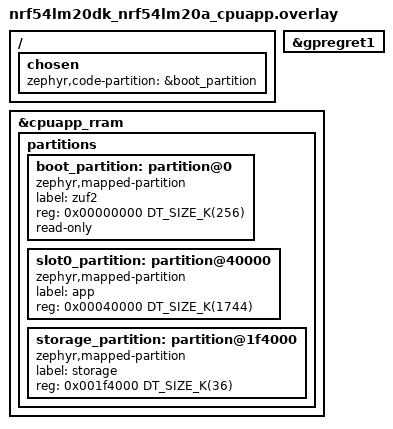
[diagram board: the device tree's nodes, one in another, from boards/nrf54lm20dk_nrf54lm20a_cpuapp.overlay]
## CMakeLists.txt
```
cmake_minimum_required(VERSION 3.20.0)

find_package(Zephyr REQUIRED HINTS $ENV{ZEPHYR_BASE})
project(zuf2)

target_include_directories(app PRIVATE src)

target_sources(app PRIVATE
	src/boot.c
	src/main.c
	src/uf2_disk.c
	src/uf2_writer.c
	src/usb_descriptors.c
)
```

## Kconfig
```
menuconfig ZUF2
	bool "zuf2 UF2 bootloader"
	default y
	help
	  Build a small UF2-over-USB-MSC bootloader that writes a
	  devicetree-defined application partition and chain-loads it directly.

if ZUF2

config ZUF2_ALWAYS_ENTER
	bool "Always stay in UF2 mode"
	default n
	help
	  Stay in the bootloader even when a valid application is present.
	  This is useful during bring-up.

config ZUF2_BOOT_BUTTON
	bool "Bootloader entry button"
	default y
	depends on GPIO
	help
	  If the board has a devicetree sw0 alias, holding it at reset keeps
	  the bootloader in UF2 mode.

config ZUF2_DOUBLE_TAP_RESET
	bool "Double-tap reset bootloader entry"
	default y
	select RETAINED_MEM if DT_HAS_NORDIC_NRF_GPREGRET_ENABLED
	help
	  Enter UF2 mode when the board is reset twice within
	  ZUF2_DOUBLE_TAP_DELAY_MS while a valid application is present.
	  This matches the common Adafruit-style double-reset bootloader
	  gesture.

config ZUF2_DOUBLE_TAP_DELAY_MS
	int "Double-tap reset window in milliseconds"
	default 500
	range 1 10000
	help
	  Time after the first reset that zuf2 waits for a second reset before
	  booting the application. This is used when ZUF2_DOUBLE_TAP_RESET is
	  enabled.

config ZUF2_DOUBLE_TAP_MAGIC
	hex "Double-tap reset marker byte"
	default 0x5a
	range 0x01 0xff
	help
	  Marker value stored in retained state during the double-tap reset
	  window. Change this if another firmware component uses the same
	  retained marker value.

config ZUF2_REQUIRE_FAMILY_ID
	bool "Require UF2 family ID"
	default y
	help
	  Only accept UF2 blocks that set the family-ID flag and match
	  ZUF2_FAMILY_ID.

config ZUF2_FAMILY_ID
	hex "UF2 family ID"
	default 0x016f65e4
	help
	  UF2 family ID accepted by this bootloader. The default was randomly
	  generated for the nRF54LM20 bring-up target because the upstream UF2
	  family list does not currently define an nRF54 family.

config ZUF2_MAX_EXTRA_UF2_BLOCKS
	int "Extra UF2 tracking blocks in blocks"
	default 2048
	help
	  Number of non-application UF2 blocks that can be tracked for
	  completion. Source-embedded UF2 files may contain blocks beyond the
	  application partition payload.

config ZUF2_RESET_DELAY_MS
	int "Reset delay after UF2 write in milliseconds"
	default 500
	help
	  Delay after all UF2 blocks have been received before rebooting into
	  the newly written application.

config ZUF2_DISK_SECTOR_COUNT
	int "Virtual UF2 disk size in sectors"
	default 8192
	help
	  Number of 512-byte sectors reported by the virtual FAT16 disk.
	  Increase this if the generated CURRENT.UF2 file does not fit.

config ZUF2_USB_VID
	hex "USB vendor ID"
	default 0x1209
	help
	  USB vendor ID used by the bootloader MSC device. Replace this for any
	  production device.

config ZUF2_USB_PID
	hex "USB product ID"
	default 0x5a02
	help
	  USB product ID used by the bootloader MSC device. Replace this for any
	  production device.

config ZUF2_USB_MANUFACTURER
	string "USB manufacturer string"
	default "zuf2"
	help
	  USB manufacturer string descriptor.

config ZUF2_USB_PRODUCT
	string "USB product string"
	default "zuf2 UF2 Bootloader"
	help
	  USB product string descriptor.

config ZUF2_VOLUME_LABEL
	string "UF2 volume label"
	default "ZUF2BOOT"
	help
	  FAT volume label. The value is padded or truncated to the FAT 11-byte
	  volume label field.

config ZUF2_MODEL
	string "UF2 model string"
	default "nRF54LM20 DK"
	help
	  Human-readable model line exposed in INFO_UF2.TXT.

config ZUF2_BOARD_ID
	string "UF2 board ID string"
	default "nRF54LM20-DK-zuf2-v0"
	help
	  Machine-readable Board-ID exposed in INFO_UF2.TXT.

config ZUF2_INDEX_URL
	string "UF2 index URL"
	default "https://github.com/microsoft/uf2"
	help
	  URL used by INDEX.HTM on the virtual UF2 disk.

module = ZUF2
module-str = zuf2 bootloader
source "$(ZEPHYR_BASE)/subsys/logging/Kconfig.template.log_config"

endif

source "Kconfig.zephyr"
```

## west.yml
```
# Copyright (c) 2021 Nordic Semiconductor ASA
# SPDX-License-Identifier: Apache-2.0

manifest:
  remotes:
    - name: ncs
      url-base: https://github.com/nrfconnect

  projects:
    - name: nrf
      remote: ncs
      repo-path: sdk-nrf
      revision: main
      import: true
```

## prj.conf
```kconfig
CONFIG_ZUF2=y
CONFIG_USE_DT_CODE_PARTITION=y

CONFIG_MAIN_STACK_SIZE=4096
CONFIG_SYSTEM_WORKQUEUE_STACK_SIZE=2048
CONFIG_BOOT_BANNER=n
CONFIG_INIT_ARCH_HW_AT_BOOT=y
CONFIG_HW_STACK_PROTECTION=y

CONFIG_LOG=y
CONFIG_ZUF2_LOG_LEVEL_INF=y
CONFIG_USBD_LOG_LEVEL_WRN=y
CONFIG_UDC_DRIVER_LOG_LEVEL_WRN=y

CONFIG_FLASH=y
CONFIG_FLASH_MAP=y
CONFIG_FLASH_PAGE_LAYOUT=y

CONFIG_DISK_ACCESS=y
CONFIG_USB_DEVICE_STACK_NEXT=y
CONFIG_USBD_MSC_CLASS=y
CONFIG_USBD_MSC_LUNS_PER_INSTANCE=1
CONFIG_USBD_MSC_SCSI_BUFFER_SIZE=512

CONFIG_REBOOT=y
CONFIG_GPIO=y
CONFIG_SERIAL=y
CONFIG_UART_LINE_CTRL=y
CONFIG_STDOUT_CONSOLE=y
CONFIG_CDC_ACM_SERIAL_INITIALIZE_AT_BOOT=n
```

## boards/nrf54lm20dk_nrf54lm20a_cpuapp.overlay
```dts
/delete-node/ &boot_partition;
/delete-node/ &slot0_partition;
/delete-node/ &slot1_partition;
/delete-node/ &storage_partition;

/ {
	chosen {
		zephyr,code-partition = &boot_partition;
	};
};

&gpregret1 {
	status = "okay";
};

&cpuapp_rram {
	partitions {
		ranges;
		#address-cells = <1>;
		#size-cells = <1>;

		boot_partition: partition@0 {
			compatible = "zephyr,mapped-partition";
			label = "zuf2";
			reg = <0x00000000 DT_SIZE_K(256)>;
			read-only;
		};

		slot0_partition: partition@40000 {
			compatible = "zephyr,mapped-partition";
			label = "app";
			reg = <0x00040000 DT_SIZE_K(1744)>;
		};

		storage_partition: partition@1f4000 {
			compatible = "zephyr,mapped-partition";
			label = "storage";
			reg = <0x001f4000 DT_SIZE_K(36)>;
		};
	};
};
```

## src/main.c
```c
#include "app_partition.h"
#include "boot.h"
#include "usb_descriptors.h"

#include <zephyr/device.h>
#include <zephyr/devicetree.h>
#include <zephyr/drivers/gpio.h>
#include <zephyr/drivers/retained_mem.h>
#include <zephyr/kernel.h>
#include <zephyr/linker/section_tags.h>
#include <zephyr/logging/log.h>

LOG_MODULE_REGISTER(zuf2, CONFIG_ZUF2_LOG_LEVEL);

#if DT_NODE_HAS_STATUS(DT_ALIAS(sw0), okay)
#define HAS_BOOT_BUTTON 1
static const struct gpio_dt_spec boot_button = GPIO_DT_SPEC_GET(DT_ALIAS(sw0), gpios);
#else
#define HAS_BOOT_BUTTON 0
#endif

#if DT_HAS_COMPAT_STATUS_OKAY(nordic_nrf_gpregret)
#define HAS_DOUBLE_TAP_RETENTION 1
static const struct device *const double_tap_retention =
	DEVICE_DT_GET(DT_INST(0, nordic_nrf_gpregret));
#else
#define HAS_DOUBLE_TAP_RETENTION 0
struct double_tap_state {
	uint32_t magic;
	uint32_t magic_inv;
	uint32_t app_base;
};
static struct double_tap_state double_tap_state __noinit;
#endif

#define DOUBLE_TAP_MAGIC ((uint8_t)CONFIG_ZUF2_DOUBLE_TAP_MAGIC)
#define DOUBLE_TAP_MAGIC_INV (~DOUBLE_TAP_MAGIC)

static bool boot_button_pressed(void)
{
	int ret;

	if (!IS_ENABLED(CONFIG_ZUF2_BOOT_BUTTON) || !HAS_BOOT_BUTTON) {
		return false;
	}

#if HAS_BOOT_BUTTON
	if (!device_is_ready(boot_button.port)) {
		LOG_WRN("boot button device is not ready");
		return false;
	}

	ret = gpio_pin_configure_dt(&boot_button, GPIO_INPUT);
	if (ret != 0) {
		LOG_WRN("failed to configure boot button: %d", ret);
		return false;
	}

	ret = gpio_pin_get_dt(&boot_button);
	if (ret < 0) {
		LOG_WRN("failed to read boot button: %d", ret);
		return false;
	}

	return ret > 0;
#else
	return false;
#endif
}

static void double_tap_clear(void)
{
#if HAS_DOUBLE_TAP_RETENTION
	int ret;

	if (!device_is_ready(double_tap_retention)) {
		return;
	}

	ret = retained_mem_clear(double_tap_retention);
	if (ret != 0) {
		LOG_WRN("failed to clear double-tap marker: %d", ret);
	}
#else
	double_tap_state.magic = 0U;
	double_tap_state.magic_inv = 0U;
	double_tap_state.app_base = 0U;
#endif
}

static bool double_tap_is_armed(void)
{
	if (!IS_ENABLED(CONFIG_ZUF2_DOUBLE_TAP_RESET)) {
		return false;
	}

#if HAS_DOUBLE_TAP_RETENTION
	uint8_t marker;
	int ret;

	if (!device_is_ready(double_tap_retention)) {
		LOG_WRN("double-tap retention device is not ready");
		return false;
	}

	ret = retained_mem_read(double_tap_retention, 0, &marker, sizeof(marker));
	if (ret != 0) {
		LOG_WRN("failed to read double-tap marker: %d", ret);
		return false;
	}

	return marker == DOUBLE_TAP_MAGIC;
#else
	return IS_ENABLED(CONFIG_ZUF2_DOUBLE_TAP_RESET) &&
	       double_tap_state.magic == (uint32_t)DOUBLE_TAP_MAGIC &&
	       double_tap_state.magic_inv == (uint32_t)DOUBLE_TAP_MAGIC_INV &&
	       double_tap_state.app_base == ZUF2_APP_PARTITION_ADDRESS;
#endif
}

static void double_tap_arm(void)
{
#if HAS_DOUBLE_TAP_RETENTION
	uint8_t marker = DOUBLE_TAP_MAGIC;
	int ret;

	if (!device_is_ready(double_tap_retention)) {
		LOG_WRN("double-tap retention device is not ready");
		return;
	}

	ret = retained_mem_write(double_tap_retention, 0, &marker, sizeof(marker));
	if (ret != 0) {
		LOG_WRN("failed to arm double-tap marker: %d", ret);
	}
#else
	double_tap_state.magic = DOUBLE_TAP_MAGIC;
	double_tap_state.magic_inv = DOUBLE_TAP_MAGIC_INV;
	double_tap_state.app_base = ZUF2_APP_PARTITION_ADDRESS;
#endif
}

static void double_tap_wait_window(void)
{
	if (!IS_ENABLED(CONFIG_ZUF2_DOUBLE_TAP_RESET)) {
		return;
	}

	k_busy_wait(CONFIG_ZUF2_DOUBLE_TAP_DELAY_MS * 1000U);
	double_tap_clear();
}

int main(void)
{
	bool double_tap_detected = false;
	bool force_uf2;
	bool app_valid;

	if (double_tap_is_armed()) {
		double_tap_clear();
		double_tap_detected = true;
	} else {
		double_tap_arm();
	}

	app_valid = zuf2_app_is_valid();
	force_uf2 = IS_ENABLED(CONFIG_ZUF2_ALWAYS_ENTER) || boot_button_pressed() ||
		    double_tap_detected;

	if (!force_uf2 && app_valid) {
		double_tap_wait_window();
		zuf2_boot_app();
	}

	double_tap_clear();

	if (double_tap_detected) {
		LOG_INF("double-tap reset detected; staying in UF2 mode");
	} else if (force_uf2) {
		LOG_INF("staying in UF2 mode");
	} else {
		LOG_INF("no valid app found; staying in UF2 mode");
	}

	return zuf2_usb_start();
}
```

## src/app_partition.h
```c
#ifndef ZUF2_APP_PARTITION_H_
#define ZUF2_APP_PARTITION_H_

#include <zephyr/storage/flash_map.h>

#if PARTITION_EXISTS(slot0_partition)
#define ZUF2_APP_PARTITION_LABEL slot0_partition
#elif PARTITION_EXISTS(code_partition)
#define ZUF2_APP_PARTITION_LABEL code_partition
#else
#error "zuf2 requires a devicetree slot0_partition or code_partition for the application"
#endif

#define ZUF2_APP_PARTITION_ID PARTITION_ID(ZUF2_APP_PARTITION_LABEL)
#define ZUF2_APP_PARTITION_OFFSET PARTITION_OFFSET(ZUF2_APP_PARTITION_LABEL)
#define ZUF2_APP_PARTITION_ADDRESS PARTITION_ADDRESS(ZUF2_APP_PARTITION_LABEL)
#define ZUF2_APP_PARTITION_SIZE PARTITION_SIZE(ZUF2_APP_PARTITION_LABEL)

#endif
```

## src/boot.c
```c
#include "app_partition.h"
#include "boot.h"

#include <cmsis_core.h>
#include <zephyr/cache.h>
#include <zephyr/devicetree.h>
#include <zephyr/kernel.h>
#include <zephyr/logging/log.h>
#include <zephyr/sys/util.h>

LOG_MODULE_DECLARE(zuf2, CONFIG_ZUF2_LOG_LEVEL);

#define SRAM_NODE DT_CHOSEN(zephyr_sram)
#define SRAM_BASE DT_REG_ADDR(SRAM_NODE)
#define SRAM_SIZE DT_REG_SIZE(SRAM_NODE)
#define SRAM_END (SRAM_BASE + SRAM_SIZE)

#define APP_BASE ZUF2_APP_PARTITION_ADDRESS
#define APP_SIZE ZUF2_APP_PARTITION_SIZE
#define APP_END (APP_BASE + APP_SIZE)

static int read_app_vectors(uint32_t *sp, uint32_t *reset)
{
	const volatile uint32_t *vectors = (const volatile uint32_t *)APP_BASE;

	/* The application is executed in place, so read vectors from that mapping. */
	*sp = vectors[0];
	*reset = vectors[1];

	return 0;
}

bool zuf2_app_is_valid(void)
{
	uint32_t sp;
	uint32_t reset;
	uint32_t reset_addr;

	if (read_app_vectors(&sp, &reset) != 0) {
		return false;
	}

	if (sp == 0xffffffffU || reset == 0xffffffffU || sp == 0U || reset == 0U) {
		return false;
	}

	if ((sp < SRAM_BASE) || (sp > SRAM_END) || ((sp & 0x7U) != 0U)) {
		LOG_WRN("invalid app stack pointer 0x%08x", sp);
		return false;
	}

	if ((reset & 0x1U) == 0U) {
		LOG_WRN("invalid app reset vector 0x%08x", reset);
		return false;
	}

	reset_addr = reset & ~0x1U;
	if ((reset_addr < APP_BASE) || (reset_addr >= APP_END)) {
		LOG_WRN("app reset vector 0x%08x outside app partition", reset);
		return false;
	}

	return true;
}

void zuf2_boot_app(void)
{
	uint32_t sp;
	uint32_t reset;

	if (read_app_vectors(&sp, &reset) != 0) {
		return;
	}

	LOG_INF("booting app at 0x%08x", APP_BASE);
	k_busy_wait(2000);

	__disable_irq();

	for (size_t i = 0; i < ARRAY_SIZE(NVIC->ICER); i++) {
		NVIC->ICER[i] = 0xffffffffU;
	}

	for (size_t i = 0; i < ARRAY_SIZE(NVIC->ICPR); i++) {
		NVIC->ICPR[i] = 0xffffffffU;
	}

	SysTick->CTRL = 0;
	SysTick->LOAD = 0;
	SysTick->VAL = 0;
	SCB->ICSR |= SCB_ICSR_PENDSTCLR_Msk;

#ifndef CONFIG_CPU_CORTEX_M0
	SCB->SHCSR &= ~(SCB_SHCSR_USGFAULTENA_Msk | SCB_SHCSR_BUSFAULTENA_Msk |
			SCB_SHCSR_MEMFAULTENA_Msk);
#endif

	if ((CONTROL_SPSEL_Msk & __get_CONTROL()) != 0U) {
		__set_CONTROL(__get_CONTROL() & ~CONTROL_SPSEL_Msk);
	}

	__DSB();
	__ISB();

#if defined(CONFIG_CPU_CORTEX_M_HAS_VTOR)
	SCB->VTOR = APP_BASE;
#endif
	(void)sys_cache_instr_invd_all();

#if defined(CONFIG_CPU_CORTEX_M_HAS_SPLIM)
	__set_PSPLIM(0);
	__set_MSPLIM(0);
#endif

	__set_PSP(0);
	__asm__ volatile(
		"msr msp, %[app_sp]\n"
		"dsb 0xf\n"
		"isb 0xf\n"
		"bx %[app_reset]\n"
		:
		: [app_sp] "r"(sp), [app_reset] "r"(reset)
		: "memory");
	CODE_UNREACHABLE;
}
```

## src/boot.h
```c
#ifndef ZUF2_BOOT_H_
#define ZUF2_BOOT_H_

#include <stdbool.h>

bool zuf2_app_is_valid(void);
void zuf2_boot_app(void);

#endif
```

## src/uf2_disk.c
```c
#include "app_partition.h"
#include "uf2_disk.h"
#include "uf2_format.h"
#include "uf2_writer.h"

#include <errno.h>
#include <stdio.h>
#include <string.h>
#include <zephyr/device.h>
#include <zephyr/drivers/disk.h>
#include <zephyr/init.h>
#include <zephyr/kernel.h>
#include <zephyr/logging/log.h>
#include <zephyr/sys/byteorder.h>
#include <zephyr/sys/util.h>

LOG_MODULE_DECLARE(zuf2, CONFIG_ZUF2_LOG_LEVEL);

#define SECTOR_SIZE 512U
#define SECTORS_PER_CLUSTER 1U
#define RESERVED_SECTORS 1U
#define FAT_COPIES 2U
#define ROOT_DIR_ENTRIES 64U
#define ROOT_DIR_SECTORS ((ROOT_DIR_ENTRIES * 32U) / SECTOR_SIZE)
#define MEDIA_DESCRIPTOR 0xf8U
#define FAT_ENTRIES_PER_SECTOR (SECTOR_SIZE / 2U)
#define SECTORS_PER_FAT                                                                 \
	((CONFIG_ZUF2_DISK_SECTOR_COUNT + FAT_ENTRIES_PER_SECTOR - 1U) /               \
	 FAT_ENTRIES_PER_SECTOR)

#define FAT0_START RESERVED_SECTORS
#define FAT1_START (FAT0_START + SECTORS_PER_FAT)
#define ROOT_DIR_START (FAT1_START + SECTORS_PER_FAT)
#define DATA_START (ROOT_DIR_START + ROOT_DIR_SECTORS)
#define DATA_SECTORS (CONFIG_ZUF2_DISK_SECTOR_COUNT - DATA_START)
#define CLUSTER_COUNT DATA_SECTORS

#define INFO_CLUSTER 2U
#define INDEX_CLUSTER 3U
#define CURRENT_CLUSTER 4U
#define CURRENT_UF2_BLOCKS                                                               \
	((ZUF2_APP_PARTITION_SIZE + UF2_DEFAULT_PAYLOAD_SIZE - 1U) /                    \
	 UF2_DEFAULT_PAYLOAD_SIZE)
#define CURRENT_UF2_SIZE (CURRENT_UF2_BLOCKS * SECTOR_SIZE)
#define CURRENT_LAST_CLUSTER (CURRENT_CLUSTER + CURRENT_UF2_BLOCKS - 1U)

BUILD_ASSERT(SECTOR_SIZE == UF2_BLOCK_SIZE);
BUILD_ASSERT(ROOT_DIR_SECTORS != 0U);
BUILD_ASSERT(CLUSTER_COUNT >= 0x1015U && CLUSTER_COUNT < 0xffd5U,
	     "virtual disk must produce a conservative FAT16 cluster count");
BUILD_ASSERT((DATA_START + (CURRENT_LAST_CLUSTER - 2U)) < CONFIG_ZUF2_DISK_SECTOR_COUNT,
	     "CONFIG_ZUF2_DISK_SECTOR_COUNT is too small for CURRENT.UF2");

static void fill_spaces(uint8_t *dst, size_t len)
{
	memset(dst, ' ', len);
}

static void write_padded(uint8_t *dst, size_t len, const char *src)
{
	fill_spaces(dst, len);
	for (size_t i = 0; i < len && src[i] != '\0'; i++) {
		dst[i] = src[i];
	}
}

static void volume_label(uint8_t label[11])
{
	write_padded(label, 11, CONFIG_ZUF2_VOLUME_LABEL);
}

static void make_boot_sector(uint8_t sector[SECTOR_SIZE])
{
	uint8_t label[11];

	memset(sector, 0, SECTOR_SIZE);
	sector[0] = 0xeb;
	sector[1] = 0x3c;
	sector[2] = 0x90;
	memcpy(&sector[3], "ZUF2    ", 8);
	sys_put_le16(SECTOR_SIZE, &sector[11]);
	sector[13] = SECTORS_PER_CLUSTER;
	sys_put_le16(RESERVED_SECTORS, &sector[14]);
	sector[16] = FAT_COPIES;
	sys_put_le16(ROOT_DIR_ENTRIES, &sector[17]);
	if (CONFIG_ZUF2_DISK_SECTOR_COUNT <= 0xffff) {
		sys_put_le16(CONFIG_ZUF2_DISK_SECTOR_COUNT, &sector[19]);
	} else {
		sys_put_le32(CONFIG_ZUF2_DISK_SECTOR_COUNT, &sector[32]);
	}
	sector[21] = MEDIA_DESCRIPTOR;
	sys_put_le16(SECTORS_PER_FAT, &sector[22]);
	sys_put_le16(1, &sector[24]);
	sys_put_le16(1, &sector[26]);
	sector[36] = 0x80;
	sector[38] = 0x29;
	sys_put_le32(0x5a554632, &sector[39]);
	volume_label(label);
	memcpy(&sector[43], label, sizeof(label));
	memcpy(&sector[54], "FAT16   ", 8);
	sector[510] = 0x55;
	sector[511] = 0xaa;
}

static uint16_t fat_entry_value(uint32_t cluster)
{
	if (cluster == 0U) {
		return 0xff00U | MEDIA_DESCRIPTOR;
	}

	if (cluster == 1U || cluster == INFO_CLUSTER || cluster == INDEX_CLUSTER) {
		return 0xffffU;
	}

	if (cluster >= CURRENT_CLUSTER && cluster <= CURRENT_LAST_CLUSTER) {
		return cluster == CURRENT_LAST_CLUSTER ? 0xffffU : (uint16_t)(cluster + 1U);
	}

	return 0U;
}

static void make_fat_sector(uint32_t fat_sector, uint8_t sector[SECTOR_SIZE])
{
	memset(sector, 0, SECTOR_SIZE);

	for (uint32_t i = 0; i < FAT_ENTRIES_PER_SECTOR; i++) {
		uint32_t cluster = fat_sector * FAT_ENTRIES_PER_SECTOR + i;

		sys_put_le16(fat_entry_value(cluster), &sector[i * 2U]);
	}
}

static void make_dir_entry(uint8_t *entry, const char name[11], uint8_t attrs,
			   uint16_t cluster, uint32_t size)
{
	memcpy(&entry[0], name, 11);
	entry[11] = attrs;
	sys_put_le16(cluster, &entry[26]);
	sys_put_le32(size, &entry[28]);
}

static int info_file(uint8_t *dst, size_t len)
{
	int ret;

	ret = snprintf((char *)dst, len,
		       "UF2 Bootloader zuf2\r\n"
		       "Model: %s\r\n"
		       "Board-ID: %s\r\n"
		       "Family-ID: 0x%08x\r\n"
		       "App-Start: 0x%08x\r\n"
		       "App-Size: %u\r\n",
		       CONFIG_ZUF2_MODEL, CONFIG_ZUF2_BOARD_ID, CONFIG_ZUF2_FAMILY_ID,
		       (uint32_t)ZUF2_APP_PARTITION_ADDRESS,
		       (uint32_t)ZUF2_APP_PARTITION_SIZE);

	return ret < 0 || ret >= (int)len ? -ENOMEM : ret;
}

static int index_file(uint8_t *dst, size_t len)
{
	int ret;

	ret = snprintf((char *)dst, len,
		       "<!doctype html>\n"
		       "<html><head><meta http-equiv=\"refresh\" content=\"0;url=%s\">"
		       "</head><body><a href=\"%s\">zuf2</a></body></html>\n",
		       CONFIG_ZUF2_INDEX_URL, CONFIG_ZUF2_INDEX_URL);

	return ret < 0 || ret >= (int)len ? -ENOMEM : ret;
}

static void make_root_dir_sector(uint32_t root_sector, uint8_t sector[SECTOR_SIZE])
{
	uint8_t label[11];
	uint8_t tmp[SECTOR_SIZE];
	uint8_t *entry;

	memset(sector, 0, SECTOR_SIZE);

	if (root_sector != 0U) {
		return;
	}

	entry = sector;
	volume_label(label);
	make_dir_entry(entry, (const char *)label, 0x08, 0, 0);

	entry += 32;
	make_dir_entry(entry, "INFO_UF2TXT", 0x20, INFO_CLUSTER, 0);
	memset(tmp, 0, sizeof(tmp));
	(void)info_file(tmp, sizeof(tmp));
	sys_put_le32(strlen((const char *)tmp), &entry[28]);

	entry += 32;
	make_dir_entry(entry, "INDEX   HTM", 0x20, INDEX_CLUSTER, 0);
	memset(tmp, 0, sizeof(tmp));
	(void)index_file(tmp, sizeof(tmp));
	sys_put_le32(strlen((const char *)tmp), &entry[28]);

	entry += 32;
	make_dir_entry(entry, "CURRENT UF2", 0x20, CURRENT_CLUSTER, CURRENT_UF2_SIZE);
}

static void make_info_sector(uint8_t sector[SECTOR_SIZE])
{
	memset(sector, 0, SECTOR_SIZE);
	(void)info_file(sector, SECTOR_SIZE);
}

static void make_index_sector(uint8_t sector[SECTOR_SIZE])
{
	memset(sector, 0, SECTOR_SIZE);
	(void)index_file(sector, SECTOR_SIZE);
}

static void make_current_uf2_sector(uint32_t uf2_block_no, uint8_t sector[SECTOR_SIZE])
{
	uint32_t app_offset = uf2_block_no * UF2_DEFAULT_PAYLOAD_SIZE;
	uint32_t remaining = ZUF2_APP_PARTITION_SIZE - app_offset;
	uint32_t payload = MIN(remaining, UF2_DEFAULT_PAYLOAD_SIZE);

	memset(sector, 0, SECTOR_SIZE);
	sys_put_le32(UF2_MAGIC_START0, &sector[0]);
	sys_put_le32(UF2_MAGIC_START1, &sector[4]);
	sys_put_le32(UF2_FLAG_FAMILY_ID, &sector[8]);
	sys_put_le32(ZUF2_APP_PARTITION_ADDRESS + app_offset, &sector[12]);
	sys_put_le32(payload, &sector[16]);
	sys_put_le32(uf2_block_no, &sector[20]);
	sys_put_le32(CURRENT_UF2_BLOCKS, &sector[24]);
	sys_put_le32(CONFIG_ZUF2_FAMILY_ID, &sector[28]);
	if (payload > 0U) {
		if (zuf2_writer_read_app(app_offset, &sector[32], payload) != 0) {
			memset(&sector[32], 0xff, payload);
		}
	}
	sys_put_le32(UF2_MAGIC_END, &sector[508]);
}

static void read_sector(uint32_t sector_no, uint8_t sector[SECTOR_SIZE])
{
	if (sector_no == 0U) {
		make_boot_sector(sector);
	} else if (sector_no < ROOT_DIR_START) {
		uint32_t fat_sector = sector_no - FAT0_START;

		if (fat_sector >= SECTORS_PER_FAT) {
			fat_sector -= SECTORS_PER_FAT;
		}
		make_fat_sector(fat_sector, sector);
	} else if (sector_no < DATA_START) {
		make_root_dir_sector(sector_no - ROOT_DIR_START, sector);
	} else {
		uint32_t cluster = (sector_no - DATA_START) + 2U;

		if (cluster == INFO_CLUSTER) {
			make_info_sector(sector);
		} else if (cluster == INDEX_CLUSTER) {
			make_index_sector(sector);
		} else if (cluster >= CURRENT_CLUSTER && cluster <= CURRENT_LAST_CLUSTER) {
			make_current_uf2_sector(cluster - CURRENT_CLUSTER, sector);
		} else {
			memset(sector, 0, SECTOR_SIZE);
		}
	}
}

static int uf2_disk_init(struct disk_info *disk)
{
	ARG_UNUSED(disk);

	return zuf2_writer_init();
}

static int uf2_disk_status(struct disk_info *disk)
{
	ARG_UNUSED(disk);

	return DISK_STATUS_OK;
}

static int uf2_disk_read(struct disk_info *disk, uint8_t *data_buf,
			 uint32_t start_sector, uint32_t num_sector)
{
	ARG_UNUSED(disk);

	if (start_sector + num_sector > CONFIG_ZUF2_DISK_SECTOR_COUNT) {
		return -EINVAL;
	}

	for (uint32_t i = 0; i < num_sector; i++) {
		read_sector(start_sector + i, &data_buf[i * SECTOR_SIZE]);
	}

	return 0;
}

static int uf2_disk_write(struct disk_info *disk, const uint8_t *data_buf,
			  uint32_t start_sector, uint32_t num_sector)
{
	int ret;

	ARG_UNUSED(disk);
	ARG_UNUSED(start_sector);

	for (uint32_t i = 0; i < num_sector; i++) {
		ret = zuf2_writer_process_sector(&data_buf[i * SECTOR_SIZE]);
		if (ret != 0) {
			return ret;
		}
	}

	return 0;
}

static int uf2_disk_erase(struct disk_info *disk, uint32_t start_sector,
			  uint32_t num_sector)
{
	ARG_UNUSED(disk);
	ARG_UNUSED(start_sector);
	ARG_UNUSED(num_sector);

	return 0;
}

static int uf2_disk_ioctl(struct disk_info *disk, uint8_t cmd, void *buff)
{
	ARG_UNUSED(disk);

	switch (cmd) {
	case DISK_IOCTL_CTRL_INIT:
	case DISK_IOCTL_CTRL_SYNC:
	case DISK_IOCTL_CTRL_DEINIT:
		return 0;
	case DISK_IOCTL_GET_SECTOR_COUNT:
		*(uint32_t *)buff = CONFIG_ZUF2_DISK_SECTOR_COUNT;
		return 0;
	case DISK_IOCTL_GET_SECTOR_SIZE:
		*(uint32_t *)buff = SECTOR_SIZE;
		return 0;
	case DISK_IOCTL_GET_ERASE_BLOCK_SZ:
		*(uint32_t *)buff = 1;
		return 0;
	default:
		return -EINVAL;
	}
}

static const struct disk_operations uf2_disk_ops = {
	.init = uf2_disk_init,
	.status = uf2_disk_status,
	.read = uf2_disk_read,
	.write = uf2_disk_write,
	.erase = uf2_disk_erase,
	.ioctl = uf2_disk_ioctl,
};

static struct disk_info uf2_disk = {
	.name = ZUF2_DISK_NAME,
	.ops = &uf2_disk_ops,
};

static int uf2_disk_register(void)
{
	int ret;

	ret = disk_access_register(&uf2_disk);
	if (ret != 0) {
		LOG_ERR("failed to register UF2 disk: %d", ret);
	}

	return ret;
}

SYS_INIT(uf2_disk_register, APPLICATION, CONFIG_APPLICATION_INIT_PRIORITY);
```

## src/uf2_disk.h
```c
#ifndef ZUF2_UF2_DISK_H_
#define ZUF2_UF2_DISK_H_

#define ZUF2_DISK_NAME "UF2"

#endif
```

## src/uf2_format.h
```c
#ifndef ZUF2_UF2_FORMAT_H_
#define ZUF2_UF2_FORMAT_H_

#include <stdint.h>
#include <zephyr/toolchain.h>

#define UF2_BLOCK_SIZE 512U
#define UF2_PAYLOAD_MAX 476U
#define UF2_DEFAULT_PAYLOAD_SIZE 256U

#define UF2_MAGIC_START0 0x0A324655UL
#define UF2_MAGIC_START1 0x9E5D5157UL
#define UF2_MAGIC_END 0x0AB16F30UL

#define UF2_FLAG_NOFLASH 0x00000001UL
#define UF2_FLAG_FILE_CONTAINER 0x00001000UL
#define UF2_FLAG_FAMILY_ID 0x00002000UL
#define UF2_FLAG_MD5_CHECKSUM 0x00004000UL
#define UF2_FLAG_EXTENSION_TAGS 0x00008000UL

struct uf2_block {
	uint32_t magic_start0;
	uint32_t magic_start1;
	uint32_t flags;
	uint32_t target_addr;
	uint32_t payload_size;
	uint32_t block_no;
	uint32_t num_blocks;
	uint32_t family_id;
	uint8_t data[UF2_PAYLOAD_MAX];
	uint32_t magic_end;
} __packed;

#endif
```

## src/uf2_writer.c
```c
#include "app_partition.h"
#include "uf2_format.h"
#include "uf2_writer.h"

#include <errno.h>
#include <string.h>
#include <zephyr/cache.h>
#include <zephyr/kernel.h>
#include <zephyr/logging/log.h>
#include <zephyr/storage/flash_map.h>
#include <zephyr/sys/byteorder.h>
#include <zephyr/sys/reboot.h>
#include <zephyr/sys/util.h>

LOG_MODULE_DECLARE(zuf2, CONFIG_ZUF2_LOG_LEVEL);

#define ZUF2_TRACKED_BLOCKS                                                                  \
	(((ZUF2_APP_PARTITION_SIZE + UF2_DEFAULT_PAYLOAD_SIZE - 1U) /                         \
	  UF2_DEFAULT_PAYLOAD_SIZE) + CONFIG_ZUF2_MAX_EXTRA_UF2_BLOCKS)

struct write_state {
	bool active;
	bool flash_prepared;
	bool complete;
	uint32_t num_blocks;
	uint32_t num_written;
	uint8_t written_mask[(ZUF2_TRACKED_BLOCKS + 7U) / 8U];
};

static const struct flash_area *app_area;
static struct write_state state;
static K_MUTEX_DEFINE(writer_lock);

static void reset_work_handler(struct k_work *work);
static K_WORK_DELAYABLE_DEFINE(reset_work, reset_work_handler);

static void reset_work_handler(struct k_work *work)
{
	ARG_UNUSED(work);

	(void)sys_cache_instr_invd_all();
	LOG_INF("resetting after UF2 update");
	sys_reboot(SYS_REBOOT_WARM);
}

int zuf2_writer_init(void)
{
	int ret;

	if (app_area != NULL) {
		return 0;
	}

	ret = flash_area_open(ZUF2_APP_PARTITION_ID, &app_area);
	if (ret != 0) {
		LOG_ERR("failed to open app flash area: %d", ret);
		return ret;
	}

	LOG_INF("app partition offset=0x%08x address=0x%08x size=%u",
		(uint32_t)app_area->fa_off, (uint32_t)ZUF2_APP_PARTITION_ADDRESS,
		(uint32_t)app_area->fa_size);

	return 0;
}

int zuf2_writer_read_app(uint32_t offset, void *buf, size_t len)
{
	int ret;

	ret = zuf2_writer_init();
	if (ret != 0) {
		return ret;
	}

	return flash_area_read(app_area, offset, buf, len);
}

static void state_begin(uint32_t num_blocks)
{
	memset(&state, 0, sizeof(state));
	state.active = true;
	state.num_blocks = num_blocks;
}

static int prepare_flash(void)
{
	int ret;

	if (state.flash_prepared) {
		return 0;
	}

	if (IS_ENABLED(CONFIG_FLASH_HAS_EXPLICIT_ERASE)) {
		LOG_INF("erasing app partition");
		ret = flash_area_flatten(app_area, 0, app_area->fa_size);
		if (ret != 0) {
			LOG_ERR("failed to erase app partition: %d", ret);
			return ret;
		}
	}

	state.flash_prepared = true;
	return 0;
}

static void mark_block_written(uint32_t block_no)
{
	uint32_t pos = block_no / 8U;
	uint8_t mask = BIT(block_no % 8U);

	if (block_no >= ZUF2_TRACKED_BLOCKS) {
		return;
	}

	if ((state.written_mask[pos] & mask) == 0U) {
		state.written_mask[pos] |= mask;
		state.num_written++;
	}
}

static void check_complete(void)
{
	if (state.complete || state.num_blocks == 0U ||
	    state.num_blocks > ZUF2_TRACKED_BLOCKS) {
		return;
	}

	if (state.num_written >= state.num_blocks) {
		state.complete = true;
		LOG_INF("UF2 write complete: %u blocks", state.num_written);
		(void)k_work_reschedule(&reset_work, K_MSEC(CONFIG_ZUF2_RESET_DELAY_MS));
	}
}

static bool uf2_magic_ok(const uint8_t sector[UF2_BLOCK_SIZE])
{
	return sys_get_le32(&sector[0]) == UF2_MAGIC_START0 &&
	       sys_get_le32(&sector[4]) == UF2_MAGIC_START1 &&
	       sys_get_le32(&sector[508]) == UF2_MAGIC_END;
}

int zuf2_writer_process_sector(const uint8_t sector[512])
{
	uint32_t flags;
	uint32_t target_addr;
	uint32_t payload_size;
	uint32_t block_no;
	uint32_t num_blocks;
	uint32_t family_id;
	uint32_t app_base = ZUF2_APP_PARTITION_ADDRESS;
	uint32_t app_size = ZUF2_APP_PARTITION_SIZE;
	uint32_t offset;
	uint32_t align;
	int ret;

	if (!uf2_magic_ok(sector)) {
		return 0;
	}

	flags = sys_get_le32(&sector[8]);
	target_addr = sys_get_le32(&sector[12]);
	payload_size = sys_get_le32(&sector[16]);
	block_no = sys_get_le32(&sector[20]);
	num_blocks = sys_get_le32(&sector[24]);
	family_id = sys_get_le32(&sector[28]);

	if ((flags & UF2_FLAG_FILE_CONTAINER) != 0U) {
		LOG_WRN("ignoring UF2 file-container block");
		return 0;
	}

	if (payload_size > UF2_PAYLOAD_MAX || num_blocks == 0U || block_no >= num_blocks) {
		LOG_ERR("invalid UF2 block metadata");
		return -EINVAL;
	}

	if (IS_ENABLED(CONFIG_ZUF2_REQUIRE_FAMILY_ID)) {
		if ((flags & UF2_FLAG_FAMILY_ID) == 0U) {
			LOG_WRN("ignoring UF2 block without family ID");
			return 0;
		}

		if (family_id != CONFIG_ZUF2_FAMILY_ID) {
			LOG_WRN("ignoring UF2 family 0x%08x", family_id);
			return 0;
		}
	}

	k_mutex_lock(&writer_lock, K_FOREVER);

	ret = zuf2_writer_init();
	if (ret != 0) {
		goto out;
	}

	if (!state.active || state.num_blocks != num_blocks) {
		if (num_blocks > ZUF2_TRACKED_BLOCKS) {
			LOG_WRN("UF2 has %u blocks; tracking limit is %u",
				num_blocks, (uint32_t)ZUF2_TRACKED_BLOCKS);
		}
		state_begin(num_blocks);
	}

	if ((flags & UF2_FLAG_NOFLASH) != 0U) {
		mark_block_written(block_no);
		check_complete();
		ret = 0;
		goto out;
	}

	if (target_addr < app_base || payload_size > app_size ||
	    target_addr > (app_base + app_size - payload_size)) {
		LOG_ERR("UF2 target 0x%08x size %u outside app partition",
			target_addr, payload_size);
		ret = -EINVAL;
		goto out;
	}

	offset = target_addr - app_base;
	align = flash_area_align(app_area);
	if (((offset % align) != 0U) || ((payload_size % align) != 0U)) {
		LOG_ERR("UF2 write is not aligned to %u bytes", align);
		ret = -EINVAL;
		goto out;
	}

	ret = prepare_flash();
	if (ret != 0) {
		goto out;
	}

	ret = flash_area_write(app_area, offset, &sector[32], payload_size);
	if (ret != 0) {
		LOG_ERR("flash write failed at 0x%08x: %d", target_addr, ret);
		goto out;
	}

	mark_block_written(block_no);
	check_complete();

out:
	k_mutex_unlock(&writer_lock);
	return ret;
}
```

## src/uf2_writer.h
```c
#ifndef ZUF2_UF2_WRITER_H_
#define ZUF2_UF2_WRITER_H_

#include <stddef.h>
#include <stdint.h>

int zuf2_writer_init(void);
int zuf2_writer_process_sector(const uint8_t sector[512]);
int zuf2_writer_read_app(uint32_t offset, void *buf, size_t len);

#endif
```

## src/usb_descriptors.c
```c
#include "uf2_disk.h"
#include "usb_descriptors.h"

#include <stdint.h>
#include <zephyr/device.h>
#include <zephyr/logging/log.h>
#include <zephyr/usb/class/usbd_msc.h>
#include <zephyr/usb/usbd.h>

LOG_MODULE_DECLARE(zuf2, CONFIG_ZUF2_LOG_LEVEL);

USBD_DEVICE_DEFINE(zuf2_usbd,
		   DEVICE_DT_GET(DT_NODELABEL(zephyr_udc0)),
		   CONFIG_ZUF2_USB_VID, CONFIG_ZUF2_USB_PID);

USBD_DESC_LANG_DEFINE(zuf2_lang);
USBD_DESC_MANUFACTURER_DEFINE(zuf2_mfr, CONFIG_ZUF2_USB_MANUFACTURER);
USBD_DESC_PRODUCT_DEFINE(zuf2_product, CONFIG_ZUF2_USB_PRODUCT);
IF_ENABLED(CONFIG_HWINFO, (USBD_DESC_SERIAL_NUMBER_DEFINE(zuf2_sn)));

USBD_DESC_CONFIG_DEFINE(zuf2_fs_desc, "UF2 FS");
USBD_DESC_CONFIG_DEFINE(zuf2_hs_desc, "UF2 HS");
USBD_CONFIGURATION_DEFINE(zuf2_fs_config, 0, 100, &zuf2_fs_desc);
USBD_CONFIGURATION_DEFINE(zuf2_hs_config, 0, 100, &zuf2_hs_desc);

USBD_DEFINE_MSC_LUN(zuf2_lun, ZUF2_DISK_NAME, "zuf2", "UF2 Boot", "0.1");

static struct usbd_context *setup_usb(void)
{
	int ret;

	ret = usbd_add_descriptor(&zuf2_usbd, &zuf2_lang);
	if (ret != 0) {
		return NULL;
	}

	ret = usbd_add_descriptor(&zuf2_usbd, &zuf2_mfr);
	if (ret != 0) {
		return NULL;
	}

	ret = usbd_add_descriptor(&zuf2_usbd, &zuf2_product);
	if (ret != 0) {
		return NULL;
	}

	IF_ENABLED(CONFIG_HWINFO, (ret = usbd_add_descriptor(&zuf2_usbd, &zuf2_sn);))
	if (ret != 0) {
		return NULL;
	}

	if (USBD_SUPPORTS_HIGH_SPEED &&
	    usbd_caps_speed(&zuf2_usbd) == USBD_SPEED_HS) {
		ret = usbd_add_configuration(&zuf2_usbd, USBD_SPEED_HS,
					     &zuf2_hs_config);
		if (ret != 0) {
			return NULL;
		}

		ret = usbd_register_all_classes(&zuf2_usbd, USBD_SPEED_HS, 1, NULL);
		if (ret != 0) {
			return NULL;
		}

		usbd_device_set_code_triple(&zuf2_usbd, USBD_SPEED_HS, 0, 0, 0);
	}

	ret = usbd_add_configuration(&zuf2_usbd, USBD_SPEED_FS, &zuf2_fs_config);
	if (ret != 0) {
		return NULL;
	}

	ret = usbd_register_all_classes(&zuf2_usbd, USBD_SPEED_FS, 1, NULL);
	if (ret != 0) {
		return NULL;
	}

	usbd_device_set_code_triple(&zuf2_usbd, USBD_SPEED_FS, 0, 0, 0);

	ret = usbd_init(&zuf2_usbd);
	if (ret != 0) {
		return NULL;
	}

	return &zuf2_usbd;
}

int zuf2_usb_start(void)
{
	struct usbd_context *ctx;
	int ret;

	ctx = setup_usb();
	if (ctx == NULL) {
		LOG_ERR("failed to initialize USB");
		return -ENODEV;
	}

	ret = usbd_enable(ctx);
	if (ret != 0) {
		LOG_ERR("failed to enable USB: %d", ret);
		return ret;
	}

	LOG_INF("UF2 MSC device is active");
	return 0;
}
```

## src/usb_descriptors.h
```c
#ifndef ZUF2_USB_DESCRIPTORS_H_
#define ZUF2_USB_DESCRIPTORS_H_

int zuf2_usb_start(void);

#endif
```
